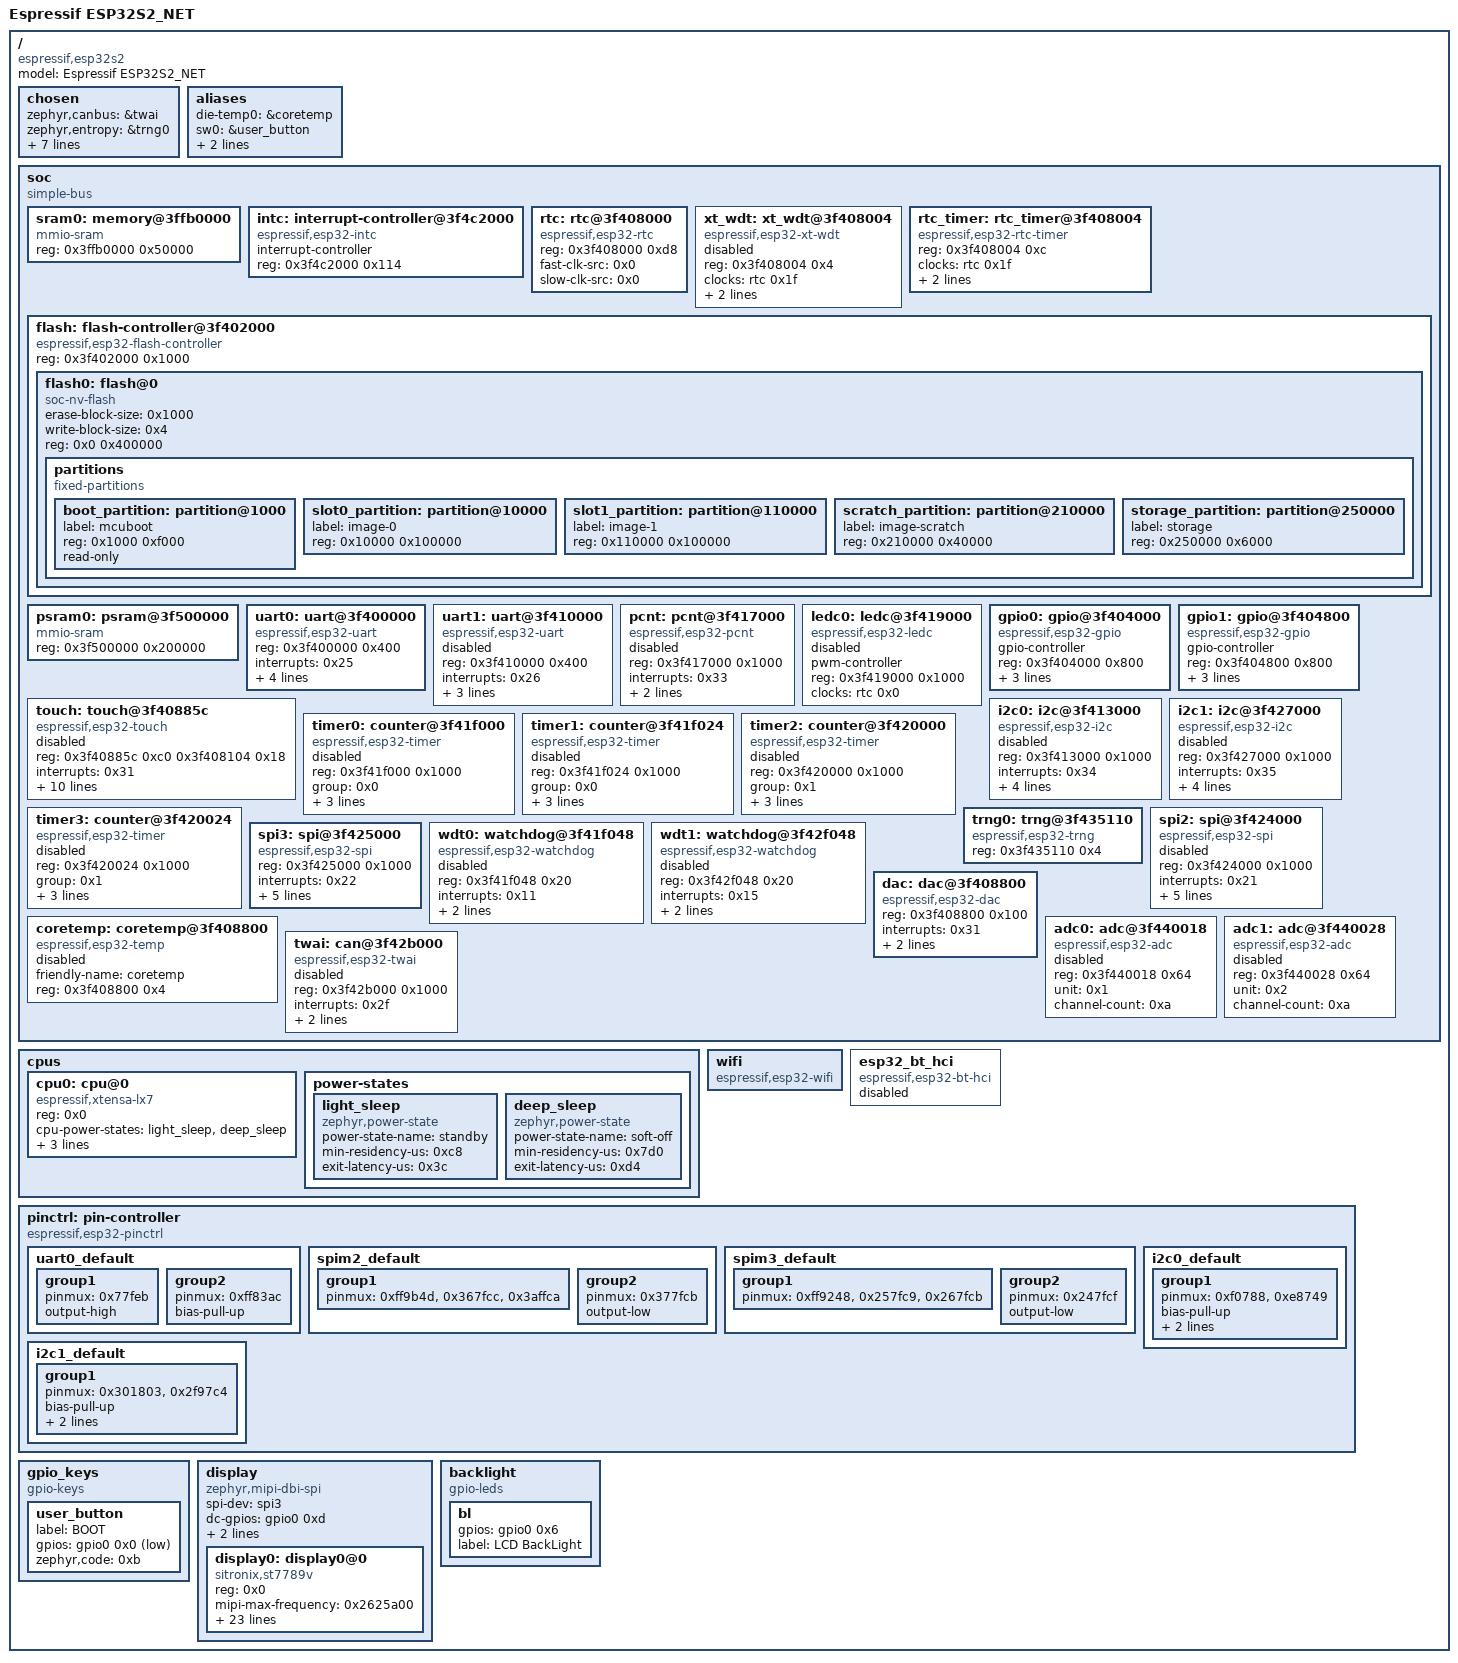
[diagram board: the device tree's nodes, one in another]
/dts-v1/;

/ {
	#address-cells = < 0x1 >;
	#size-cells = < 0x1 >;
	model = "Espressif ESP32S2_NET";
	compatible = "espressif,esp32s2";
	chosen {
		zephyr,canbus = &twai;
		zephyr,entropy = &trng0;
		zephyr,flash-controller = &flash;
		zephyr,sram = &sram0;
		zephyr,console = &uart0;
		zephyr,shell-uart = &uart0;
		zephyr,flash = &flash0;
		zephyr,code-partition = &slot0_partition;
		zephyr,display = &display0;
	};
	aliases {
		die-temp0 = &coretemp;
		sw0 = &user_button;
		i2c-0 = &i2c0;
		watchdog0 = &wdt0;
	};
	soc {
		#address-cells = < 0x1 >;
		#size-cells = < 0x1 >;
		compatible = "simple-bus";
		ranges;
		sram0: memory@3ffb0000 {
			compatible = "mmio-sram";
			reg = < 0x3ffb0000 0x50000 >;
		};
		intc: interrupt-controller@3f4c2000 {
			#interrupt-cells = < 0x1 >;
			compatible = "espressif,esp32-intc";
			interrupt-controller;
			reg = < 0x3f4c2000 0x114 >;
			status = "okay";
			phandle = < 0x2 >;
		};
		rtc: rtc@3f408000 {
			compatible = "espressif,esp32-rtc";
			reg = < 0x3f408000 0xd8 >;
			fast-clk-src = < 0x0 >;
			slow-clk-src = < 0x0 >;
			#clock-cells = < 0x1 >;
			status = "okay";
			phandle = < 0x1 >;
		};
		xt_wdt: xt_wdt@3f408004 {
			compatible = "espressif,esp32-xt-wdt";
			reg = < 0x3f408004 0x4 >;
			clocks = < &rtc 0x1f >;
			interrupts = < 0x31 >;
			interrupt-parent = < &intc >;
			status = "disabled";
		};
		rtc_timer: rtc_timer@3f408004 {
			reg = < 0x3f408004 0xc >;
			compatible = "espressif,esp32-rtc-timer";
			clocks = < &rtc 0x1f >;
			interrupts = < 0x31 >;
			interrupt-parent = < &intc >;
			status = "okay";
		};
		flash: flash-controller@3f402000 {
			compatible = "espressif,esp32-flash-controller";
			reg = < 0x3f402000 0x1000 >;
			#address-cells = < 0x1 >;
			#size-cells = < 0x1 >;
			flash0: flash@0 {
				compatible = "soc-nv-flash";
				erase-block-size = < 0x1000 >;
				write-block-size = < 0x4 >;
				reg = < 0x0 0x400000 >;
				status = "okay";
				partitions {
					compatible = "fixed-partitions";
					#address-cells = < 0x1 >;
					#size-cells = < 0x1 >;
					boot_partition: partition@1000 {
						label = "mcuboot";
						reg = < 0x1000 0xf000 >;
						read-only;
					};
					slot0_partition: partition@10000 {
						label = "image-0";
						reg = < 0x10000 0x100000 >;
					};
					slot1_partition: partition@110000 {
						label = "image-1";
						reg = < 0x110000 0x100000 >;
					};
					scratch_partition: partition@210000 {
						label = "image-scratch";
						reg = < 0x210000 0x40000 >;
					};
					storage_partition: partition@250000 {
						label = "storage";
						reg = < 0x250000 0x6000 >;
					};
				};
			};
		};
		psram0: psram@3f500000 {
			device_type = "memory";
			compatible = "mmio-sram";
			reg = < 0x3f500000 0x200000 >;
			status = "okay";
		};
		uart0: uart@3f400000 {
			compatible = "espressif,esp32-uart";
			reg = < 0x3f400000 0x400 >;
			status = "okay";
			interrupts = < 0x25 >;
			interrupt-parent = < &intc >;
			clocks = < &rtc 0x1 >;
			current-speed = < 0x1c200 >;
			pinctrl-0 = < &uart0_default >;
			pinctrl-names = "default";
		};
		uart1: uart@3f410000 {
			compatible = "espressif,esp32-uart";
			reg = < 0x3f410000 0x400 >;
			status = "disabled";
			interrupts = < 0x26 >;
			interrupt-parent = < &intc >;
			clocks = < &rtc 0x2 >;
			current-speed = < 0x1c200 >;
		};
		pcnt: pcnt@3f417000 {
			compatible = "espressif,esp32-pcnt";
			reg = < 0x3f417000 0x1000 >;
			interrupts = < 0x33 >;
			interrupt-parent = < &intc >;
			clocks = < &rtc 0xc >;
			status = "disabled";
		};
		ledc0: ledc@3f419000 {
			compatible = "espressif,esp32-ledc";
			pwm-controller;
			#pwm-cells = < 0x3 >;
			reg = < 0x3f419000 0x1000 >;
			clocks = < &rtc 0x0 >;
			status = "disabled";
		};
		gpio0: gpio@3f404000 {
			compatible = "espressif,esp32-gpio";
			gpio-controller;
			#gpio-cells = < 0x2 >;
			reg = < 0x3f404000 0x800 >;
			interrupts = < 0x17 >;
			interrupt-parent = < &intc >;
			ngpios = < 0x20 >;
			status = "okay";
			phandle = < 0xa >;
		};
		gpio1: gpio@3f404800 {
			compatible = "espressif,esp32-gpio";
			gpio-controller;
			#gpio-cells = < 0x2 >;
			reg = < 0x3f404800 0x800 >;
			interrupts = < 0x17 >;
			interrupt-parent = < &intc >;
			ngpios = < 0x16 >;
			status = "okay";
		};
		touch: touch@3f40885c {
			compatible = "espressif,esp32-touch";
			reg = < 0x3f40885c 0xc0 0x3f408104 0x18 >;
			interrupts = < 0x31 >;
			interrupt-parent = < &intc >;
			status = "disabled";
			debounce-interval-ms = < 0x1e >;
			href-microvolt = < 0x2932e0 >;
			lref-microvolt = < 0x7a120 >;
			href-atten-microvolt = < 0xf4240 >;
			filter-mode = < 0x2 >;
			filter-debounce-cnt = < 0x1 >;
			filter-noise-thr = < 0x0 >;
			filter-jitter-step = < 0x4 >;
			filter-smooth-level = < 0x1 >;
		};
		i2c0: i2c@3f413000 {
			compatible = "espressif,esp32-i2c";
			#address-cells = < 0x1 >;
			#size-cells = < 0x0 >;
			reg = < 0x3f413000 0x1000 >;
			interrupts = < 0x34 >;
			interrupt-parent = < &intc >;
			clocks = < &rtc 0x4 >;
			status = "disabled";
			clock-frequency = < 0x186a0 >;
			pinctrl-0 = < &i2c0_default >;
			pinctrl-names = "default";
		};
		i2c1: i2c@3f427000 {
			compatible = "espressif,esp32-i2c";
			#address-cells = < 0x1 >;
			#size-cells = < 0x0 >;
			reg = < 0x3f427000 0x1000 >;
			interrupts = < 0x35 >;
			interrupt-parent = < &intc >;
			clocks = < &rtc 0x5 >;
			status = "disabled";
			clock-frequency = < 0x186a0 >;
			pinctrl-0 = < &i2c1_default >;
			pinctrl-names = "default";
		};
		timer0: counter@3f41f000 {
			compatible = "espressif,esp32-timer";
			reg = < 0x3f41f000 0x1000 >;
			group = < 0x0 >;
			index = < 0x0 >;
			interrupts = < 0xf >;
			interrupt-parent = < &intc >;
			status = "disabled";
		};
		timer1: counter@3f41f024 {
			compatible = "espressif,esp32-timer";
			reg = < 0x3f41f024 0x1000 >;
			group = < 0x0 >;
			index = < 0x1 >;
			interrupts = < 0x10 >;
			interrupt-parent = < &intc >;
			status = "disabled";
		};
		timer2: counter@3f420000 {
			compatible = "espressif,esp32-timer";
			reg = < 0x3f420000 0x1000 >;
			group = < 0x1 >;
			index = < 0x0 >;
			interrupts = < 0x13 >;
			interrupt-parent = < &intc >;
			status = "disabled";
		};
		timer3: counter@3f420024 {
			compatible = "espressif,esp32-timer";
			reg = < 0x3f420024 0x1000 >;
			group = < 0x1 >;
			index = < 0x1 >;
			interrupts = < 0x14 >;
			interrupt-parent = < &intc >;
			status = "disabled";
		};
		trng0: trng@3f435110 {
			compatible = "espressif,esp32-trng";
			reg = < 0x3f435110 0x4 >;
			status = "okay";
		};
		spi2: spi@3f424000 {
			compatible = "espressif,esp32-spi";
			reg = < 0x3f424000 0x1000 >;
			interrupts = < 0x21 >;
			interrupt-parent = < &intc >;
			clocks = < &rtc 0xe >;
			dma-clk = < 0x10 >;
			dma-host = < 0x0 >;
			status = "disabled";
			#address-cells = < 0x1 >;
			#size-cells = < 0x0 >;
			pinctrl-0 = < &spim2_default >;
			pinctrl-names = "default";
		};
		spi3: spi@3f425000 {
			compatible = "espressif,esp32-spi";
			reg = < 0x3f425000 0x1000 >;
			interrupts = < 0x22 >;
			interrupt-parent = < &intc >;
			clocks = < &rtc 0xf >;
			dma-clk = < 0x11 >;
			dma-host = < 0x1 >;
			status = "okay";
			#address-cells = < 0x1 >;
			#size-cells = < 0x0 >;
			pinctrl-0 = < &spim3_default >;
			pinctrl-names = "default";
			phandle = < 0xb >;
		};
		wdt0: watchdog@3f41f048 {
			compatible = "espressif,esp32-watchdog";
			reg = < 0x3f41f048 0x20 >;
			interrupts = < 0x11 >;
			interrupt-parent = < &intc >;
			clocks = < &rtc 0x7 >;
			status = "disabled";
		};
		wdt1: watchdog@3f42f048 {
			compatible = "espressif,esp32-watchdog";
			reg = < 0x3f42f048 0x20 >;
			interrupts = < 0x15 >;
			interrupt-parent = < &intc >;
			clocks = < &rtc 0x8 >;
			status = "disabled";
		};
		dac: dac@3f408800 {
			compatible = "espressif,esp32-dac";
			reg = < 0x3f408800 0x100 >;
			interrupts = < 0x31 >;
			interrupt-parent = < &intc >;
			clocks = < &rtc 0x1e >;
			#io-channel-cells = < 0x1 >;
			status = "okay";
		};
		coretemp: coretemp@3f408800 {
			compatible = "espressif,esp32-temp";
			friendly-name = "coretemp";
			reg = < 0x3f408800 0x4 >;
			status = "disabled";
		};
		adc0: adc@3f440018 {
			compatible = "espressif,esp32-adc";
			reg = < 0x3f440018 0x64 >;
			unit = < 0x1 >;
			channel-count = < 0xa >;
			#io-channel-cells = < 0x1 >;
			status = "disabled";
		};
		adc1: adc@3f440028 {
			compatible = "espressif,esp32-adc";
			reg = < 0x3f440028 0x64 >;
			unit = < 0x2 >;
			channel-count = < 0xa >;
			#io-channel-cells = < 0x1 >;
			status = "disabled";
		};
		twai: can@3f42b000 {
			compatible = "espressif,esp32-twai";
			reg = < 0x3f42b000 0x1000 >;
			interrupts = < 0x2f >;
			interrupt-parent = < &intc >;
			clocks = < &rtc 0x12 >;
			status = "disabled";
		};
	};
	cpus {
		#address-cells = < 0x1 >;
		#size-cells = < 0x0 >;
		cpu0: cpu@0 {
			device_type = "cpu";
			compatible = "espressif,xtensa-lx7";
			reg = < 0x0 >;
			cpu-power-states = < &light_sleep &deep_sleep >;
			clock-source = < 0x1 >;
			clock-frequency = < 0xe4e1c00 >;
			xtal-freq = < 0x2625a00 >;
		};
		power-states {
			light_sleep: light_sleep {
				compatible = "zephyr,power-state";
				power-state-name = "standby";
				min-residency-us = < 0xc8 >;
				exit-latency-us = < 0x3c >;
				phandle = < 0x8 >;
			};
			deep_sleep: deep_sleep {
				compatible = "zephyr,power-state";
				power-state-name = "soft-off";
				min-residency-us = < 0x7d0 >;
				exit-latency-us = < 0xd4 >;
				phandle = < 0x9 >;
			};
		};
	};
	wifi: wifi {
		compatible = "espressif,esp32-wifi";
		status = "okay";
	};
	esp32_bt_hci: esp32_bt_hci {
		compatible = "espressif,esp32-bt-hci";
		status = "disabled";
	};
	pinctrl: pin-controller {
		compatible = "espressif,esp32-pinctrl";
		status = "okay";
		uart0_default: uart0_default {
			phandle = < 0x3 >;
			group1 {
				pinmux = < 0x77feb >;
				output-high;
			};
			group2 {
				pinmux = < 0xff83ac >;
				bias-pull-up;
			};
		};
		spim2_default: spim2_default {
			phandle = < 0x6 >;
			group1 {
				pinmux = < 0xff9b4d >, < 0x367fcc >, < 0x3affca >;
			};
			group2 {
				pinmux = < 0x377fcb >;
				output-low;
			};
		};
		spim3_default: spim3_default {
			phandle = < 0x7 >;
			group1 {
				pinmux = < 0xff9248 >, < 0x257fc9 >, < 0x267fcb >;
			};
			group2 {
				pinmux = < 0x247fcf >;
				output-low;
			};
		};
		i2c0_default: i2c0_default {
			phandle = < 0x4 >;
			group1 {
				pinmux = < 0xf0788 >, < 0xe8749 >;
				bias-pull-up;
				drive-open-drain;
				output-high;
			};
		};
		i2c1_default: i2c1_default {
			phandle = < 0x5 >;
			group1 {
				pinmux = < 0x301803 >, < 0x2f97c4 >;
				bias-pull-up;
				drive-open-drain;
				output-high;
			};
		};
	};
	gpio_keys {
		compatible = "gpio-keys";
		user_button: user_button {
			label = "BOOT";
			gpios = < &gpio0 0x0 0x11 >;
			zephyr,code = < 0xb >;
		};
	};
	display: display {
		status = "okay";
		compatible = "zephyr,mipi-dbi-spi";
		spi-dev = < &spi3 >;
		dc-gpios = < &gpio0 0xd 0x0 >;
		reset-gpios = < &gpio0 0x10 0x1 >;
		write-only;
		#address-cells = < 0x1 >;
		#size-cells = < 0x0 >;
		display0: display0@0 {
			compatible = "sitronix,st7789v";
			status = "okay";
			reg = < 0x0 >;
			mipi-max-frequency = < 0x2625a00 >;
			mipi-mode = < 0x2 >;
			height = < 0xf0 >;
			width = < 0x140 >;
			x-offset = < 0x0 >;
			y-offset = < 0x0 >;
			vcom = < 0x2b >;
			gctrl = < 0x35 >;
			vrhs = < 0xf >;
			vdvs = < 0x20 >;
			mdac = < 0x60 >;
			lcm = < 0x2c >;
			colmod = < 0x55 >;
			gamma = < 0x1 >;
			inversion-off;
			porch-param = [ 0C 0C 00 33 33 ];
			cmd2en-param = [ 5A 69 02 01 ];
			pwctrl1-param = [ 52 A1 ];
			pvgam-param = [ D0 00 02 07 0B 1A 31 54 40 29 12 12 12 17 ];
			nvgam-param = [ D0 00 02 07 05 15 2D 44 44 1C 18 16 1C 1D ];
			ram-param = [ 00 F8 ];
			rgb-param = [ CD 08 14 ];
		};
	};
	backlight: backlight {
		compatible = "gpio-leds";
		bl: bl {
			gpios = < &gpio0 0x6 0x0 >;
			label = "LCD BackLight";
		};
	};
};
